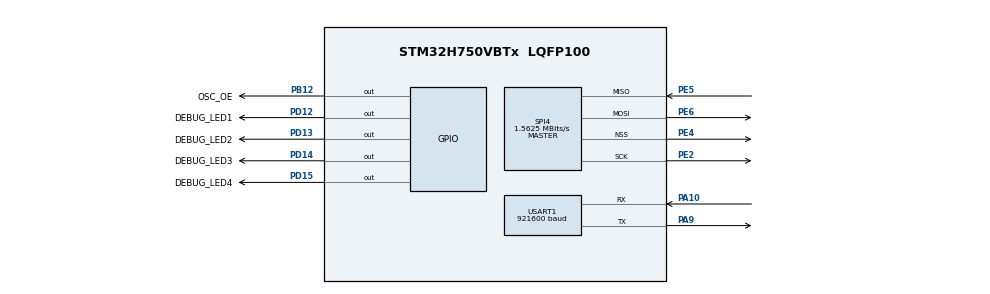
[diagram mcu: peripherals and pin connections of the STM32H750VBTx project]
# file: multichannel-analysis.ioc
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Dma.Request0=SPI4_RX
Dma.Request1=SPI4_TX
Dma.SPI4_RX.0.Direction=DMA_PERIPH_TO_MEMORY
Dma.SPI4_RX.0.EventEnable=DISABLE
Dma.SPI4_RX.0.FIFOMode=DMA_FIFOMODE_DISABLE
Dma.SPI4_RX.0.Instance=DMA1_Stream0
Dma.SPI4_RX.0.MemDataAlignment=DMA_MDATAALIGN_BYTE
Dma.SPI4_RX.0.MemInc=DMA_MINC_ENABLE
Dma.SPI4_RX.0.Mode=DMA_NORMAL
Dma.SPI4_RX.0.PeriphDataAlignment=DMA_PDATAALIGN_BYTE
Dma.SPI4_RX.0.PeriphInc=DMA_PINC_DISABLE
Dma.SPI4_RX.0.Polarity=HAL_DMAMUX_REQ_GEN_RISING
Dma.SPI4_RX.0.Priority=DMA_PRIORITY_LOW
Dma.SPI4_RX.0.RequestNumber=1
Dma.SPI4_RX.0.SignalID=NONE
Dma.SPI4_RX.0.SyncEnable=DISABLE
Dma.SPI4_RX.0.SyncPolarity=HAL_DMAMUX_SYNC_NO_EVENT
Dma.SPI4_RX.0.SyncRequestNumber=1
Dma.SPI4_RX.0.SyncSignalID=NONE
Dma.SPI4_TX.1.Direction=DMA_MEMORY_TO_PERIPH
Dma.SPI4_TX.1.EventEnable=DISABLE
Dma.SPI4_TX.1.FIFOMode=DMA_FIFOMODE_DISABLE
Dma.SPI4_TX.1.Instance=DMA1_Stream1
Dma.SPI4_TX.1.MemDataAlignment=DMA_MDATAALIGN_BYTE
Dma.SPI4_TX.1.MemInc=DMA_MINC_ENABLE
Dma.SPI4_TX.1.Mode=DMA_NORMAL
Dma.SPI4_TX.1.PeriphDataAlignment=DMA_PDATAALIGN_BYTE
Dma.SPI4_TX.1.PeriphInc=DMA_PINC_DISABLE
Dma.SPI4_TX.1.Polarity=HAL_DMAMUX_REQ_GEN_RISING
Dma.SPI4_TX.1.Priority=DMA_PRIORITY_LOW
Dma.SPI4_TX.1.RequestNumber=1
Dma.SPI4_TX.1.SignalID=NONE
Dma.SPI4_TX.1.SyncEnable=DISABLE
Dma.SPI4_TX.1.SyncPolarity=HAL_DMAMUX_SYNC_NO_EVENT
Dma.SPI4_TX.1.SyncRequestNumber=1
Dma.SPI4_TX.1.SyncSignalID=NONE
Mcu.Family=STM32H7
Mcu.Name=STM32H750VBTx
Mcu.Package=LQFP100
NVIC.DMA1_Stream0_IRQn=true\:0\:0\:false\:false\:true\:false\:true
NVIC.DMA1_Stream1_IRQn=true\:0\:0\:false\:false\:true\:false\:true
NVIC.PriorityGroup=NVIC_PRIORITYGROUP_4
NVIC.SPI4_IRQn=true\:0\:0\:false\:false\:true\:false\:true
NVIC.USART1_IRQn=true\:0\:0\:false\:false\:true\:true\:true
PA10.Mode=Asynchronous
PA10.Signal=USART1_RX
PA13\ (JTMS/SWDIO).Mode=Serial_Wire
PA13\ (JTMS/SWDIO).Signal=DEBUG_JTMS-SWDIO
PA14\ (JTCK/SWCLK).Mode=Serial_Wire
PA14\ (JTCK/SWCLK).Signal=DEBUG_JTCK-SWCLK
PA9.Mode=Asynchronous
PA9.Signal=USART1_TX
PB12.GPIO_Label=OSC_OE
PB12.Signal=GPIO_Output
PB3\ (JTDO/TRACESWO).Signal=DEBUG_JTDO-SWO
PD12.GPIO_Label=DEBUG_LED1
PD12.Signal=GPIO_Output
PD13.GPIO_Label=DEBUG_LED2
PD13.Signal=GPIO_Output
PD14.GPIO_Label=DEBUG_LED3
PD14.Signal=GPIO_Output
PD15.GPIO_Label=DEBUG_LED4
PD15.Signal=GPIO_Output
PE2.Mode=Full_Duplex_Master
PE2.Signal=SPI4_SCK
PE4.Mode=NSS_Signal_Hard_Output
PE4.Signal=SPI4_NSS
PE5.Mode=Full_Duplex_Master
PE5.Signal=SPI4_MISO
PE6.Mode=Full_Duplex_Master
PE6.Signal=SPI4_MOSI
PH0-OSC_IN\ (PH0).Mode=HSE-External-Clock-Source
PH0-OSC_IN\ (PH0).Signal=RCC_OSC_IN
ProjectManager.HeapSize=0x200
ProjectManager.StackSize=0x400
ProjectManager.TargetToolchain=Makefile
RCC.ADCFreq_Value=50390625
RCC.APB1Freq_Value=100000000
RCC.APB2Freq_Value=100000000
RCC.APB3Freq_Value=100000000
RCC.APB4Freq_Value=100000000
RCC.CortexFreq_Value=400000000
RCC.D1PPRE=RCC_APB3_DIV2
RCC.D2PPRE1=RCC_APB1_DIV2
RCC.D2PPRE2=RCC_APB2_DIV2
RCC.D3PPRE=RCC_APB4_DIV2
RCC.DIVM1=5
RCC.DIVN1=160
RCC.HCLKFreq_Value=200000000
RCC.HPRE=RCC_HCLK_DIV2
RCC.PLLSourceVirtual=RCC_PLLSOURCE_HSE
RCC.SYSCLKFreq_VALUE=400000000
RCC.SYSCLKSource=RCC_SYSCLKSOURCE_PLLCLK
RCC.USBFreq_Value=400000000
SPI4.BaudRatePrescaler=SPI_BAUDRATEPRESCALER_64
SPI4.CalculateBaudRate=1.5625 MBits/s
SPI4.DataSize=SPI_DATASIZE_8BIT
SPI4.Direction=SPI_DIRECTION_2LINES
SPI4.Mode=SPI_MODE_MASTER
SPI4.TIMode=SPI_TIMODE_DISABLE
SPI4.VirtualNSS=VM_NSSHARD
SPI4.VirtualType=VM_MASTER
USART1.BaudRate=921600
USART1.VirtualMode-Asynchronous=VM_ASYNC
board=custom

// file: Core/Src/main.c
/* USER CODE BEGIN Header */
/**
  ******************************************************************************
  * @file           : main.c
  * @brief          : Main program body
  ******************************************************************************
  * @attention
  *
  * <h2><center>&copy; Copyright (c) 2020 STMicroelectronics.
  * All rights reserved.</center></h2>
  *
  * This software component is licensed by ST under BSD 3-Clause license,
  * the "License"; You may not use this file except in compliance with the
  * License. You may obtain a copy of the License at:
  *                        opensource.org/licenses/BSD-3-Clause
  *
  ******************************************************************************
  */
/* USER CODE END Header */

#include "main.h"
#include "dma.h"
#include "spi.h"
#include "usart.h"
#include "gpio.h"

/* USER CODE BEGIN Includes */
#include "app-init.h"
/* USER CODE END Includes */

void SystemClock_Config(void);

int main(void)
{

  /* MCU Configuration--------------------------------------------------------*/

  /* Reset of all peripherals, Initializes the Flash interface and the Systick. */
  HAL_Init();

  /* Configure the system clock */
  SystemClock_Config();

  /* Initialize all configured peripherals */
  MX_GPIO_Init();
  MX_DMA_Init();
  MX_SPI4_Init();
  MX_USART1_UART_Init();
  /* USER CODE BEGIN 2 */
  app_init();
  /* USER CODE END 2 */

  /* Infinite loop */
  while (1)
  {

  }
}

void SystemClock_Config(void)
{
  RCC_OscInitTypeDef RCC_OscInitStruct = {0};
  RCC_ClkInitTypeDef RCC_ClkInitStruct = {0};
  RCC_PeriphCLKInitTypeDef PeriphClkInitStruct = {0};

  /** Supply configuration update enable
  */
  HAL_PWREx_ConfigSupply(PWR_LDO_SUPPLY);
  /** Configure the main internal regulator output voltage
  */
  __HAL_PWR_VOLTAGESCALING_CONFIG(PWR_REGULATOR_VOLTAGE_SCALE1);

  while(!__HAL_PWR_GET_FLAG(PWR_FLAG_VOSRDY)) {}
  /** Initializes the CPU, AHB and APB busses clocks
  */
  RCC_OscInitStruct.OscillatorType = RCC_OSCILLATORTYPE_HSE;
  RCC_OscInitStruct.HSEState = RCC_HSE_BYPASS;
  RCC_OscInitStruct.PLL.PLLState = RCC_PLL_ON;
  RCC_OscInitStruct.PLL.PLLSource = RCC_PLLSOURCE_HSE;
  RCC_OscInitStruct.PLL.PLLM = 5;
  RCC_OscInitStruct.PLL.PLLN = 160;
  RCC_OscInitStruct.PLL.PLLP = 2;
  RCC_OscInitStruct.PLL.PLLQ = 2;
  RCC_OscInitStruct.PLL.PLLR = 2;
  RCC_OscInitStruct.PLL.PLLRGE = RCC_PLL1VCIRANGE_2;
  RCC_OscInitStruct.PLL.PLLVCOSEL = RCC_PLL1VCOWIDE;
  RCC_OscInitStruct.PLL.PLLFRACN = 0;
  if (HAL_RCC_OscConfig(&RCC_OscInitStruct) != HAL_OK)
  {
    Error_Handler();
  }
  /** Initializes the CPU, AHB and APB busses clocks
  */
  RCC_ClkInitStruct.ClockType = RCC_CLOCKTYPE_HCLK|RCC_CLOCKTYPE_SYSCLK
                              |RCC_CLOCKTYPE_PCLK1|RCC_CLOCKTYPE_PCLK2
                              |RCC_CLOCKTYPE_D3PCLK1|RCC_CLOCKTYPE_D1PCLK1;
  RCC_ClkInitStruct.SYSCLKSource = RCC_SYSCLKSOURCE_PLLCLK;
  RCC_ClkInitStruct.SYSCLKDivider = RCC_SYSCLK_DIV1;
  RCC_ClkInitStruct.AHBCLKDivider = RCC_HCLK_DIV2;
  RCC_ClkInitStruct.APB3CLKDivider = RCC_APB3_DIV2;
  RCC_ClkInitStruct.APB1CLKDivider = RCC_APB1_DIV2;
  RCC_ClkInitStruct.APB2CLKDivider = RCC_APB2_DIV2;
  RCC_ClkInitStruct.APB4CLKDivider = RCC_APB4_DIV2;

  if (HAL_RCC_ClockConfig(&RCC_ClkInitStruct, FLASH_LATENCY_2) != HAL_OK)
  {
    Error_Handler();
  }
  PeriphClkInitStruct.PeriphClockSelection = RCC_PERIPHCLK_USART1|RCC_PERIPHCLK_SPI4;
  PeriphClkInitStruct.Spi45ClockSelection = RCC_SPI45CLKSOURCE_D2PCLK1;
  PeriphClkInitStruct.Usart16ClockSelection = RCC_USART16CLKSOURCE_D2PCLK2;
  if (HAL_RCCEx_PeriphCLKConfig(&PeriphClkInitStruct) != HAL_OK)
  {
    Error_Handler();
  }
}

void Error_Handler(void)
{
}

/************************ (C) COPYRIGHT STMicroelectronics *****END OF FILE****/
